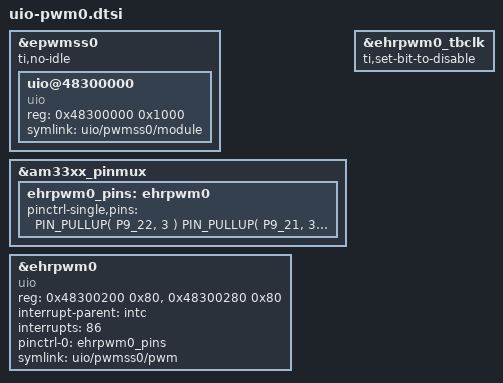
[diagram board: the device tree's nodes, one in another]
#include "bone/black.h"

// make sure subsystem is enabled and make it usable for uio
&epwmss0 {
	status = "okay";

	// ask kernel to keep its clocks enabled at all times
	ti,no-idle;

	// make sure the entire subsystem's range is mapped
	ranges = <0x48300000 0x48300000 0x1000>;

	// the entire subsystem's registers is a single 4K page so we make a
	// uio device for that.  the submodule uio devices are mainly for the
	// irq (with the declared register ranges just being informative).
	uio@48300000 {
		reg = <0x48300000 0x1000>;

		compatible = "uio";
		symlink = "uio/pwmss0/module";
	};
};



USES_PIN( P9_21 );  // ehrpwm 0 out B
USES_PIN( P9_22 );  // ehrpwm 0 out A

&am33xx_pinmux {
	ehrpwm0_pins: ehrpwm0 {
		pinctrl-single,pins = <
			// both pins are typically driven so I could use NOPULL
			// to save a tiny bit of power consumption, but it is
			// possible to make ehrpwm disable its outputs so just
			// leave pull-up enabled (which is the default pull for
			// these pins) to ensure they're never floating.
			PIN_PULLUP( P9_22, 3 )	// out A
			PIN_PULLUP( P9_21, 3 )	// out B
		>;
	};
};

&ehrpwm0 {
	status = "okay";

	// main DT neglects the HR registers
	reg = <0x48300200 0x80>, <0x48300280 0x80>;
	reg-names = "pwm", "hr";

	// interrupt declaration missing in main DT
	interrupt-parent = <&intc>;
	interrupts = <86>;

	pinctrl-names = "default";
	pinctrl-0 = <&ehrpwm0_pins>;

	compatible = "uio";
	symlink = "uio/pwmss0/pwm";
};

// XXX it appears impossible to convince the kernel to enable tbclk, so make it
// think the enable-bit has inverted meaning instead.  yes, this is disgusting.
&ehrpwm0_tbclk {
	ti,set-bit-to-disable;
};
